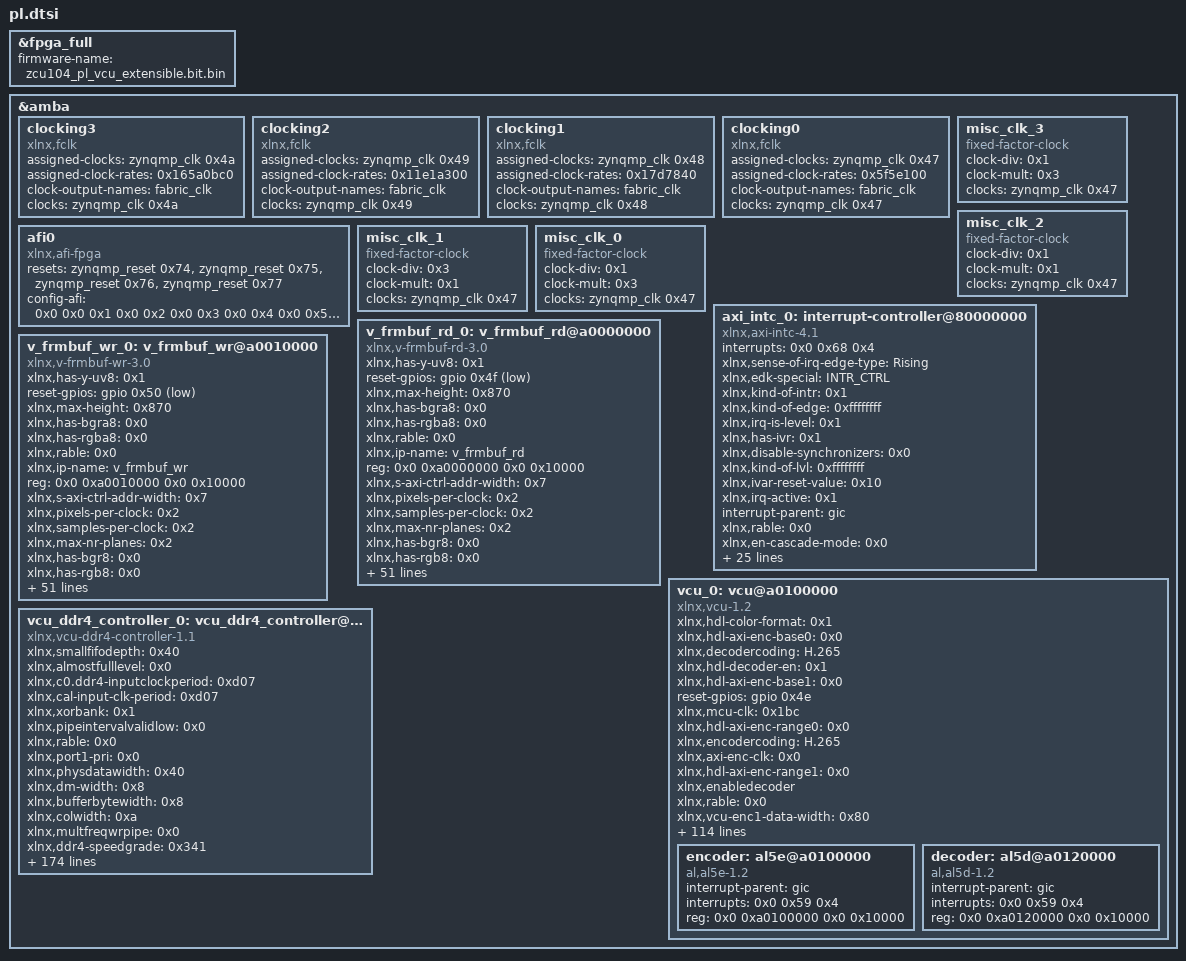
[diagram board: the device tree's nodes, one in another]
/dts-v1/;
/plugin/;
&fpga_full{
	firmware-name = "zcu104_pl_vcu_extensible.bit.bin";
};
&amba{
	clocking3: clocking3 {
		compatible = "xlnx,fclk";
		status = "okay";
		assigned-clocks = <&zynqmp_clk 0x4a>;
		assigned-clock-rates = <0x165a0bc0>;
		#clock-cells = <0x0>;
		clock-output-names = "fabric_clk";
		clocks = <&zynqmp_clk 0x4a>;
	};
	clocking2: clocking2 {
		compatible = "xlnx,fclk";
		status = "okay";
		assigned-clocks = <&zynqmp_clk 0x49>;
		assigned-clock-rates = <0x11e1a300>;
		#clock-cells = <0x0>;
		clock-output-names = "fabric_clk";
		clocks = <&zynqmp_clk 0x49>;
	};
	clocking1: clocking1 {
		compatible = "xlnx,fclk";
		status = "okay";
		assigned-clocks = <&zynqmp_clk 0x48>;
		assigned-clock-rates = <0x17d7840>;
		#clock-cells = <0x0>;
		clock-output-names = "fabric_clk";
		clocks = <&zynqmp_clk 0x48>;
	};
	clocking0: clocking0 {
		compatible = "xlnx,fclk";
		status = "okay";
		assigned-clocks = <&zynqmp_clk 0x47>;
		assigned-clock-rates = <0x5f5e100>;
		#clock-cells = <0x0>;
		clock-output-names = "fabric_clk";
		clocks = <&zynqmp_clk 0x47>;
	};
	afi0: afi0 {
		status = "okay";
		compatible = "xlnx,afi-fpga";
		resets = <&zynqmp_reset 0x74>,
<&zynqmp_reset 0x75>,
<&zynqmp_reset 0x76>,
<&zynqmp_reset 0x77>;
		config-afi = <0x0 0x0 0x1 0x0 0x2 0x0 0x3 0x0 0x4 0x0 0x5 0x0 0x6 0x0 0x7 0x0 0x8 0x0 0x9 0x0 0xa 0x0 0xb 0x0 0xc 0x0 0xd 0x0 0xe 0xa00 0xf 0x0>;
	};
};
&amba{
	misc_clk_3: misc_clk_3 {
		clock-div = <0x1>;
		compatible = "fixed-factor-clock";
		clock-mult = <0x3>;
		clocks = <&zynqmp_clk 0x47>;
		#clock-cells = <0x0>;
	};
	misc_clk_2: misc_clk_2 {
		clock-div = <0x1>;
		compatible = "fixed-factor-clock";
		clock-mult = <0x1>;
		clocks = <&zynqmp_clk 0x47>;
		#clock-cells = <0x0>;
	};
	misc_clk_1: misc_clk_1 {
		clock-div = <0x3>;
		compatible = "fixed-factor-clock";
		clock-mult = <0x1>;
		clocks = <&zynqmp_clk 0x47>;
		#clock-cells = <0x0>;
	};
	misc_clk_0: misc_clk_0 {
		clock-div = <0x1>;
		compatible = "fixed-factor-clock";
		clock-mult = <0x3>;
		clocks = <&zynqmp_clk 0x47>;
		#clock-cells = <0x0>;
	};
	axi_intc_0: interrupt-controller@80000000 {
		#interrupt-cells = <0x2>;
		interrupts = <0x0 0x68 0x4>;
		xlnx,sense-of-irq-edge-type = "Rising";
		xlnx,edk-special = "INTR_CTRL";
		xlnx,kind-of-intr = <0x1>;
		xlnx,kind-of-edge = <0xffffffff>;
		xlnx,irq-is-level = <0x1>;
		xlnx,has-ivr = <0x1>;
		compatible = "xlnx,axi-intc-4.1", "xlnx,xps-intc-1.00.a";
		xlnx,disable-synchronizers = <0x0>;
		xlnx,kind-of-lvl = <0xffffffff>;
		xlnx,ivar-reset-value = <0x10>;
		xlnx,irq-active = <0x1>;
		interrupt-parent = <&gic>;
		xlnx,rable = <0x0>;
		xlnx,en-cascade-mode = <0x0>;
		xlnx,ip-name = "axi_intc";
		xlnx,has-ilr = <0x0>;
		reg = <0x0 0x80000000 0x0 0x10000>;
		xlnx,addr-width = <0x20>;
		clocks = <&zynqmp_clk 0x47>;
		xlnx,s-axi-aclk-freq-mhz = <0x64>;
		xlnx,num-sw-intr = <0x0>;
		xlnx,irq-connection = <0x1>;
		xlnx,num-intr-inputs = <0x1>;
		xlnx,has-sie = <0x1>;
		xlnx,enable-async = <0x0>;
		xlnx,has-cie = <0x1>;
		xlnx,num-sync-ff = <0x2>;
		xlnx,edk-iptype = "PERIPHERAL";
		xlnx,mb-clk-not-connected = <0x1>;
		xlnx,has-ipr = <0x1>;
		xlnx,sense-of-irq-level-type = "Active_High";
		xlnx,cascade-master = <0x0>;
		xlnx,processor-clk-freq-mhz = <0x64>;
		status = "okay";
		xlnx,is-fast = <0x0>;
		clock-names = "s_axi_aclk";
		xlnx,has-fast = <0x0>;
		xlnx,ivar-rst-val = <0x10>;
		interrupt-controller;
		interrupt-names = "irq";
		xlnx,async-intr = <0xffffffff>;
		xlnx,name = "axi_intc_0";
	};
	v_frmbuf_rd_0: v_frmbuf_rd@a0000000 {
		xlnx,has-y-uv8 = <0x1>;
		reset-gpios = <&gpio 0x4f 0x1>;
		xlnx,max-height = <0x870>;
		xlnx,has-bgra8 = <0x0>;
		xlnx,has-rgba8 = <0x0>;
		xlnx,rable = <0x0>;
		xlnx,ip-name = "v_frmbuf_rd";
		reg = <0x0 0xa0000000 0x0 0x10000>;
		xlnx,s-axi-ctrl-addr-width = <0x7>;
		xlnx,pixels-per-clock = <0x2>;
		xlnx,samples-per-clock = <0x2>;
		xlnx,max-nr-planes = <0x2>;
		xlnx,has-bgr8 = <0x0>;
		xlnx,has-rgb8 = <0x0>;
		xlnx,has-y-uv8-420 = <0x1>;
		xlnx,has-yuyv8 = <0x0>;
		xlnx,has-y-u-v8 = <0x0>;
		interrupt-names = "interrupt";
		compatible = "xlnx,v-frmbuf-rd-3.0", "xlnx,axi-frmbuf-rd-v2.2";
		xlnx,max-width = <0xf00>;
		xlnx,has-rgb16 = <0x0>;
		xlnx,vid-formats = "y8", "y10", "nv12", "nv16", "xv20", "xv15";
		xlnx,has-bgrx8 = <0x0>;
		xlnx,has-rgbx8 = <0x0>;
		xlnx,has-rgbx10 = <0x0>;
		interrupt-parent = <&gic>;
		xlnx,aximm-num-outstanding = <0x4>;
		xlnx,has-uyvy8 = <0x0>;
		xlnx,has-rgbx12 = <0x0>;
		xlnx,aximm-burst-length = <0x10>;
		xlnx,aximm-addr-width = <0x40>;
		xlnx,video-width = <0xa>;
		xlnx,max-cols = <0xf00>;
		xlnx,has-yuv8 = <0x0>;
		status = "okay";
		xlnx,has-y-uv10-420 = <0x1>;
		xlnx,has-yuva8 = <0x0>;
		xlnx,has-y-uv12-420 = <0x0>;
		xlnx,name = "v_frmbuf_rd_0";
		interrupts = <0x0 0x5a 0x4>;
		xlnx,has-y10 = <0x1>;
		xlnx,has-y-uv16-420 = <0x0>;
		xlnx,has-y12 = <0x0>;
		xlnx,has-alpha = <0x0>;
		xlnx,has-y-u-v10 = <0x0>;
		clocks = <&misc_clk_0>;
		xlnx,has-y16 = <0x0>;
		xlnx,dma-align = <0x10>;
		xlnx,has-y-u-v12 = <0x0>;
		xlnx,edk-iptype = "PERIPHERAL";
		xlnx,has-interlaced = <0x0>;
		xlnx,has-yuv16 = <0x0>;
		xlnx,has-yuvx8 = <0x0>;
		xlnx,is-tile-format = <0x0>;
		xlnx,dma-addr-width = <0x40>;
		clock-names = "ap_clk";
		xlnx,s-axi-ctrl-data-width = <0x20>;
		xlnx,has-y8 = <0x1>;
		xlnx,has-y-uv10 = <0x1>;
		xlnx,has-y-uv12 = <0x0>;
		xlnx,max-rows = <0x870>;
		xlnx,has-yuvx10 = <0x0>;
		#dma-cells = <0x1>;
		xlnx,has-yuvx12 = <0x0>;
		xlnx,has-y-uv16 = <0x0>;
		xlnx,max-data-width = <0xa>;
		xlnx,has-y-u-v8-420 = <0x0>;
		xlnx,num-video-components = <0x3>;
		xlnx,aximm-data-width = <0x80>;
	};
	v_frmbuf_wr_0: v_frmbuf_wr@a0010000 {
		xlnx,has-y-uv8 = <0x1>;
		reset-gpios = <&gpio 0x50 0x1>;
		xlnx,max-height = <0x870>;
		xlnx,has-bgra8 = <0x0>;
		xlnx,has-rgba8 = <0x0>;
		xlnx,rable = <0x0>;
		xlnx,ip-name = "v_frmbuf_wr";
		reg = <0x0 0xa0010000 0x0 0x10000>;
		xlnx,s-axi-ctrl-addr-width = <0x7>;
		xlnx,pixels-per-clock = <0x2>;
		xlnx,samples-per-clock = <0x2>;
		xlnx,max-nr-planes = <0x2>;
		xlnx,has-bgr8 = <0x0>;
		xlnx,has-rgb8 = <0x0>;
		xlnx,has-y-uv8-420 = <0x1>;
		xlnx,has-yuyv8 = <0x0>;
		xlnx,has-y-u-v8 = <0x0>;
		interrupt-names = "interrupt";
		compatible = "xlnx,v-frmbuf-wr-3.0", "xlnx,axi-frmbuf-wr-v2.2";
		xlnx,max-width = <0xf00>;
		xlnx,has-rgb16 = <0x0>;
		xlnx,vid-formats = "y8", "y10", "nv12", "nv16", "xv20", "xv15";
		xlnx,has-bgrx8 = <0x0>;
		xlnx,has-rgbx8 = <0x0>;
		xlnx,has-rgbx10 = <0x0>;
		interrupt-parent = <&gic>;
		xlnx,aximm-num-outstanding = <0x4>;
		xlnx,has-uyvy8 = <0x0>;
		xlnx,has-rgbx12 = <0x0>;
		xlnx,aximm-burst-length = <0x10>;
		xlnx,aximm-addr-width = <0x20>;
		xlnx,video-width = <0xa>;
		xlnx,max-cols = <0xf00>;
		xlnx,has-yuv8 = <0x0>;
		status = "okay";
		xlnx,has-y-uv10-420 = <0x1>;
		xlnx,has-yuva8 = <0x0>;
		xlnx,has-y-uv12-420 = <0x0>;
		xlnx,name = "v_frmbuf_wr_0";
		interrupts = <0x0 0x5b 0x4>;
		xlnx,has-y10 = <0x1>;
		xlnx,has-y-uv16-420 = <0x0>;
		xlnx,has-y12 = <0x0>;
		xlnx,has-alpha = <0x0>;
		xlnx,has-y-u-v10 = <0x0>;
		clocks = <&misc_clk_0>;
		xlnx,has-y16 = <0x0>;
		xlnx,dma-align = <0x10>;
		xlnx,has-y-u-v12 = <0x0>;
		xlnx,edk-iptype = "PERIPHERAL";
		xlnx,has-interlaced = <0x0>;
		xlnx,has-yuv16 = <0x0>;
		xlnx,has-yuvx8 = <0x0>;
		xlnx,is-tile-format = <0x0>;
		xlnx,dma-addr-width = <0x20>;
		clock-names = "ap_clk";
		xlnx,s-axi-ctrl-data-width = <0x20>;
		xlnx,has-y8 = <0x1>;
		xlnx,has-y-uv10 = <0x1>;
		xlnx,has-y-uv12 = <0x0>;
		xlnx,max-rows = <0x870>;
		xlnx,has-yuvx10 = <0x0>;
		#dma-cells = <0x1>;
		xlnx,has-yuvx12 = <0x0>;
		xlnx,has-y-uv16 = <0x0>;
		xlnx,max-data-width = <0xa>;
		xlnx,has-y-u-v8-420 = <0x0>;
		xlnx,num-video-components = <0x3>;
		xlnx,aximm-data-width = <0x80>;
	};
	vcu_0: vcu@a0100000 {
		xlnx,hdl-color-format = <0x1>;
		xlnx,hdl-axi-enc-base0 = <0x0>;
		xlnx,decodercoding = "H.265";
		xlnx,hdl-decoder-en = <0x1>;
		xlnx,hdl-axi-enc-base1 = <0x0>;
		reset-gpios = <&gpio 0x4e 0x0>;
		xlnx,mcu-clk = <0x1bc>;
		xlnx,hdl-axi-enc-range0 = <0x0>;
		xlnx,encodercoding = "H.265";
		xlnx,axi-enc-clk = <0x0>;
		xlnx,hdl-axi-enc-range1 = <0x0>;
		xlnx,enabledecoder;
		xlnx,rable = <0x0>;
		xlnx,vcu-enc1-data-width = <0x80>;
		xlnx,dec-video-standard = <0x0>;
		xlnx,pll-bypass = <0x0>;
		xlnx,hdl-dec-fps = <0x3c>;
		xlnx,encverresolution = <0x870>;
		xlnx,enc-mem-bram-used = <0x0>;
		xlnx,ip-name = "vcu";
		#size-cells = <0x2>;
		reg = <0x0 0xa0140000 0x0 0x1000 0x0 0xa0141000 0x0 0x1000>;
		xlnx,hdl-enc-clk = <0x0>;
		xlnx,hdl-enc-buffer-en = <0x1>;
		#address-cells = <0x2>;
		xlnx,hdl-axi-mcu-range = <0x0>;
		xlnx,vcu-dec0-data-width = <0x80>;
		xlnx,enc-fps = <0x1>;
		xlnx,dec-coding-type = <0x1>;
		xlnx,axi-enc-range0 = <0x0>;
		interrupt-names = "vcu_host_interrupt";
		xlnx,hdl-vcu-test-en = <0x0>;
		xlnx,hdl-coding-type = <0x1>;
		xlnx,enc-color-format = <0x1>;
		xlnx,axi-enc-range1 = <0x0>;
		xlnx,decoderchromaformat = "4_2_2";
		compatible = "xlnx,vcu-1.2", "xlnx,vcu";
		xlnx,vcu-axiliteapb-data-width = <0x20>;
		xlnx,dec-color-depth = <0x1>;
		xlnx,enable-encoder;
		xlnx,hdl-encoder-en = <0x1>;
		xlnx,decverresolution = <0x870>;
		interrupt-parent = <&gic>;
		xlnx,hdl-dec-frame-size-x = <0xf00>;
		xlnx,hdl-color-depth = <0x1>;
		xlnx,hdl-dec-frame-size-y = <0x870>;
		xlnx,hdl-axi-mcu-clk = <0x40533333>;
		xlnx,enc-video-standard = <0x0>;
		ranges;
		xlnx,enc-mem-uram-used = <0x6ae>;
		xlnx,decodernumcores = <0x2>;
		xlnx,no-of-streams = <0x8>;
		xlnx,hdl-dec-video-standard = <0x0>;
		xlnx,axi-mcu-clk = <0x14a>;
		xlnx,hdl-pll-bypass = <0x0>;
		xlnx,enc-buffer-manual-override = <0x0>;
		status = "okay";
		xlnx,dec-color-format = <0x1>;
		xlnx,pll-clk = <0x1fca055>;
		xlnx,hdl-test-port-en = <0x0>;
		xlnx,hdl-axi-dec-clk = <0x0>;
		xlnx,hdl-mcu-clk = <0x1bc>;
		xlnx,hdl-axi-mcu-base = <0x0>;
		xlnx,name = "vcu_0";
		interrupts = <0x0 0x59 0x4>;
		xlnx,table-no = <0x1>;
		xlnx,axi-dec-clk = <0x0>;
		xlnx,hdl-dec-color-format = <0x1>;
		xlnx,hdl-ram-type = <0x0>;
		xlnx,hdl-pll-clk-lo = <0x20>;
		xlnx,enc-buffer-size-actual = <0x6ae>;
		xlnx,vcu-dec1-data-width = <0x80>;
		xlnx,vcu-mcu-data-width = <0x20>;
		xlnx,dec-frame-size = <0x4>;
		xlnx,enc-buffer-size = <0x5f0>;
		xlnx,hdl-table-no = <0x1>;
		xlnx,enableencoder;
		clocks = <&misc_clk_1>,
<&misc_clk_2>,
<&vcu_0 0x0>,
<&vcu_0 0x1>,
<&vcu_0 0x2>,
<&vcu_0 0x3>;
		xlnx,hdl-dec-coding-type = <0x1>;
		xlnx,hdl-video-standard = <0x0>;
		xlnx,dec-fps = <0x3>;
		xlnx,edk-iptype = "PERIPHERAL";
		xlnx,enc-buffer-b-frame = <0x1>;
		xlnx,enc-clk = <0x0>;
		xlnx,vcu-enc0-data-width = <0x80>;
		xlnx,hdl-fps = <0x1e>;
		xlnx,enc-coding-type = <0x1>;
		clock-names = "pll_ref", "aclk", "vcu_core_enc", "vcu_mcu_enc", "vcu_core_dec", "vcu_mcu_dec";
		xlnx,hdl-dec-color-depth = <0x1>;
		xlnx,hdl-enc-buffer-motion-vec-range = <0x0>;
		xlnx,hdl-enc-buffer-manual-override = <0x0>;
		xlnx,hdl-axi-dec-range0 = <0x0>;
		xlnx,enable-decoder;
		xlnx,hdl-axi-dec-range1 = <0x0>;
		xlnx,encoderchromaformat = "4_2_2";
		xlnx,enchorresolution = <0xf00>;
		xlnx,axi-dec-base0 = <0x0>;
		xlnx,no-of-dec-streams = <0x1>;
		xlnx,hdl-wpp-en = <0x0>;
		xlnx,enc-color-depth = <0x1>;
		xlnx,enc-buffer-type = <0x0>;
		xlnx,axi-dec-base1 = <0x0>;
		xlnx,decodercodingtype = "INTRA_ONLY";
		xlnx,hdl-frame-size-x = <0x780>;
		xlnx,axi-enc-base0 = <0x0>;
		xlnx,enc-buffer-motion-vec-range = <0x0>;
		xlnx,hdl-frame-size-y = <0x438>;
		xlnx,encodercodingtype = "INTRA_ONLY";
		xlnx,enc-frame-size = <0x3>;
		xlnx,axi-enc-base1 = <0x0>;
		xlnx,core-clk = <0x29b>;
		xlnx,hdl-num-concurrent-streams = <0x4>;
		xlnx,hdl-pll-clk-hi = <0x21>;
		xlnx,decodercolordepth = <0xa>;
		xlnx,encodernumcores = <0x4>;
		xlnx,encodercolordepth = <0xa>;
		xlnx,axi-mcu-base = <0x0>;
		xlnx,hdl-core-clk = <0x29b>;
		xlnx,axi-dec-range0 = <0x0>;
		xlnx,enc-buffer-en;
		xlnx,hdl-mem-depth = <0x9800>;
		xlnx,axi-dec-range1 = <0x0>;
		xlnx,axi-mcu-range = <0x0>;
		xlnx,wpp-en = <0x0>;
		xlnx,hdl-axi-dec-base0 = <0x0>;
		reg-names = "vcu_slcr", "logicore";
		#clock-cells = <0x1>;
		xlnx,mcu-debug = <0x0>;
		xlnx,hdl-num-streams = <0x8>;
		xlnx,hdl-max-num-cores = <0x4>;
		xlnx,hdl-enc-buffer-b-frame = <0x1>;
		xlnx,hdl-axi-enc-clk = <0x0>;
		xlnx,hdl-axi-dec-base1 = <0x0>;
		xlnx,coreclkfreq = <0x29b>;
		xlnx,dechorresolution = <0xf00>;
	
		encoder: al5e@a0100000 {
			interrupt-parent = <&gic>;
			interrupts = <0x0 0x59 0x4>;
			compatible = "al,al5e-1.2", "al,al5e";
			reg = <0x0 0xa0100000 0x0 0x10000>;
		};
		decoder: al5d@a0120000 {
			interrupt-parent = <&gic>;
			interrupts = <0x0 0x59 0x4>;
			compatible = "al,al5d-1.2", "al,al5d";
			reg = <0x0 0xa0120000 0x0 0x10000>;
		};
		};
	vcu_ddr4_controller_0: vcu_ddr4_controller@4800000000 {
		xlnx,smallfifodepth = <0x40>;
		xlnx,almostfulllevel = <0x0>;
		xlnx,c0.ddr4-inputclockperiod = <0xd07>;
		xlnx,cal-input-clk-period = <0xd07>;
		xlnx,xorbank = <0x1>;
		xlnx,pipeintervalvalidlow = <0x0>;
		xlnx,rable = <0x0>;
		xlnx,port1-pri = <0x0>;
		xlnx,physdatawidth = <0x40>;
		xlnx,dm-width = <0x8>;
		xlnx,bufferbytewidth = <0x8>;
		xlnx,colwidth = <0xa>;
		xlnx,multfreqwrpipe = <0x0>;
		xlnx,ddr4-speedgrade = <0x341>;
		xlnx,ip-name = "vcu_ddr4_controller";
		xlnx,port3-pri = <0x1>;
		xlnx,pipeintervalwaithigh = <0x3>;
		xlnx,ddr4-custompartsfile = "no_file_loaded";
		reg = <0x48 0x0 0x0 0x80000000>;
		xlnx,usrwrpipe = <0x1>;
		xlnx,nbseq = <0x1>;
		xlnx,logenable = <0x0>;
		xlnx,data-buf-addr-width = <0x5>;
		xlnx,cust-ddr4-timeperiod = <0x341>;
		xlnx,hdl-port0-en = <0x1>;
		xlnx,dualclock = <0x0>;
		xlnx,ddr4-cmdgetaddr = <0x16>;
		xlnx,writedelay = <0x7>;
		xlnx,burstlength = <0x8>;
		xlnx,nbchipselect = <0x1>;
		xlnx,iaddrwidth = <0x16>;
		xlnx,bankwidth = <0x4>;
		xlnx,bufferdatawidth = <0x80>;
		xlnx,clkout1-divide-mmcm = <0x6>;
		xlnx,nbfifo = <0x10>;
		xlnx,odtend = <0x6>;
		xlnx,nrtr = <0xd>;
		xlnx,dram-width-hdl = <0x0>;
		xlnx,divclk-divide-mmcm = <0x3>;
		xlnx,cust-csv-memtype = "Components";
		xlnx,ddr4-cust-file-en = <0x0>;
		xlnx,data-width = <0x0>;
		xlnx,cwlatency = <0xe>;
		compatible = "xlnx,vcu-ddr4-controller-1.1";
		xlnx,c0-ddr4-divclk-divide = <0x3>;
		xlnx,nrtw = <0x3>;
		xlnx,cmdrep = <0x0>;
		xlnx,speed-bin-hdl = <0x1>;
		xlnx,areset = <0x0>;
		xlnx,c0-ddr4-clkfbout-mult = <0x10>;
		xlnx,nodatacmdslot = <0x3>;
		xlnx,hdl-port3-en = <0x1>;
		xlnx,dimm-value-hdl = <0x0>;
		xlnx,ddr4-sdrambank = <0x10>;
		xlnx,trfc = <0x104>;
		xlnx,physaddrwidth = <0x11>;
		xlnx,wrpipe = <0x1>;
		xlnx,caslatency = <0xf>;
		xlnx,c0.ddr4-clkout0-divide = <0x6>;
		xlnx,drivestrength = <0x0>;
		xlnx,ddr4-cmdflag = <0x10>;
		xlnx,rddatafifopipe = <0x1>;
		xlnx,resetlevel = <0x1>;
		xlnx,ref-clk = <0x12c>;
		xlnx,nfaw = <0x6>;
		xlnx,maxpostedrefresh = <0x1>;
		xlnx,ddr4-cmdwait = <0x10>;
		xlnx,cust-csv-clkout2-freq = <0x12c>;
		xlnx,twr = <0xf>;
		xlnx,coldelay = <0x4>;
		xlnx,writegrouping = <0x20>;
		status = "okay";
		xlnx,c0.ddr4-timeperiod = <0x3aa>;
		xlnx,port0-pri-idx = <0x1>;
		xlnx,dbgmoncntsize = <0x10>;
		xlnx,c0.controllertype = "ddr4_sdram";
		xlnx,combineaxiburst = <0x1>;
		xlnx,rowwidth = <0xf>;
		xlnx,port1-pri-idx = <0x2>;
		xlnx,port2-pri-idx = <0x4>;
		xlnx,enable-port0;
		xlnx,name = "vcu_ddr4_controller_0";
		xlnx,usrburstwidth = <0x8>;
		xlnx,tck = <0x3aa>;
		xlnx,port3-pri-idx = <0x5>;
		xlnx,enable-port1;
		xlnx,ddr = <0x4>;
		xlnx,port4-pri-idx = <0x3>;
		xlnx,nwtr = <0x7>;
		xlnx,no-of-axi-ports = <0x5>;
		xlnx,nbcke = <0x1>;
		xlnx,hdl-port1-en = <0x1>;
		xlnx,enable-port2;
		xlnx,cust-enable = <0x0>;
		xlnx,c0.ddr4-divclk-divide = <0x3>;
		xlnx,incrburst = <0x0>;
		xlnx,fastfaw = <0x0>;
		xlnx,enable-port3;
		xlnx,nbbank = <0x10>;
		xlnx,port0-pri = <0x0>;
		xlnx,enable-port4;
		xlnx,dqs-width = <0x8>;
		xlnx,c0.ddr4-clkfbout-mult = <0x10>;
		xlnx,trace-length = <0x3>;
		xlnx,clkinperiodmmcm = <0xd07>;
		xlnx,readgrouping = <0x60>;
		xlnx,port2-pri = <0x1>;
		xlnx,ping-pong = <0x1>;
		xlnx,cust-csv-datawidth = <0x40>;
		xlnx,nwtw = <0x10>;
		xlnx,multfreq = <0x1>;
		xlnx,memory-timeperiod = <0x64>;
		xlnx,dram-speed-bin = <0x2>;
		xlnx,ddr4-customparts = "no_file_loaded";
		clocks = <&misc_clk_3>;
		xlnx,regcmdaddrincr = <0x0>;
		xlnx,port4-pri = <0x0>;
		xlnx,addrpipe = <0x0>;
		xlnx,nbhiprior-ports = <0x3>;
		xlnx,pipeintervalvalidhigh = <0x3>;
		xlnx,addrwidth = <0x1a>;
		xlnx,ck-width = <0x1>;
		xlnx,clkout0-divide-mmcm = <0x6>;
		xlnx,edk-iptype = "PERIPHERAL";
		xlnx,perrd = <0x1>;
		xlnx,addn-ui-clkout2-freq-hz = <0x10b>;
		xlnx,clkout2-divide-mmcm = <0x6>;
		xlnx,hdl-port4-en = <0x1>;
		xlnx,fifo-depth = <0x100>;
		xlnx,ddr4-cmdstrobe = <0x10>;
		xlnx,bg-width = <0x1>;
		xlnx,c0-controllertype = <0x0>;
		xlnx,choose-ram = <0x0>;
		xlnx,clkfboutmultmmcm = <0x10>;
		xlnx,nrrd = <0x1>;
		clock-names = "S_Axi_Clk";
		xlnx,trpa = <0x3a96>;
		xlnx,nzqcs = <0x40>;
		xlnx,maddrwidth = <0x1a>;
		xlnx,ddr4-cmdtoken = <0x10>;
		xlnx,wrpipebram = <0x1>;
		xlnx,replicatefract = <0x1>;
		xlnx,dram-width = <0x0>;
		xlnx,ddr4-tck-op = <0x2ee>;
		xlnx,trefi = <0x1e78>;
		xlnx,ref-clk-var = <0xd07>;
		xlnx,enable-decoder;
		xlnx,axi-addrwidth = <0x20>;
		xlnx,waitfast = <0x0>;
		xlnx,maxdatasize = <0x800>;
		xlnx,ddraxiburstratio = <0x2>;
		xlnx,wr-port0-pri-idx = <0x1>;
		xlnx,odtstart = <0x4>;
		xlnx,wr-port1-pri-idx = <0x2>;
		xlnx,tzqcsi = <0x100>;
		xlnx,rdpipebram = <0x0>;
		xlnx,part-sg = <0x2>;
		xlnx,mc-bg = <0xf>;
		xlnx,nrrd-s = <0x0>;
		xlnx,clkout2-divide = <0x6>;
		xlnx,wr-port2-pri-idx = <0x3>;
		xlnx,chipgrouping = <0x4>;
		xlnx,wrack = <0x1>;
		xlnx,wr-port3-pri-idx = <0x4>;
		xlnx,is-cke-shared = <0x0>;
		xlnx,active-axi-ports = <0x5>;
		xlnx,wr-port4-pri-idx = <0x5>;
		xlnx,ddr4-op-clk = <0x12c>;
		xlnx,csv-file-en = <0x0>;
		xlnx,bankgroupwidth = <0x2>;
		xlnx,compbits = <0x2710>;
		xlnx,pipeintervalwaitlow = <0x0>;
		xlnx,gui-csv-ddr4-custompartsfile = "no_file_loaded";
		xlnx,gui-csv-ddr4-customparts = "no_file_loaded";
		xlnx,ddr4-inputclk-period-ip = <0x9c4>;
		xlnx,usrflag = <0x10>;
		xlnx,rdpipe = <0x0>;
		xlnx,odt-width = <0x1>;
		xlnx,norefresh = <0x0>;
		xlnx,hdl-port2-en = <0x1>;
		xlnx,hdl-nobuffer = <0x0>;
		xlnx,dqwidth = <0x40>;
		xlnx,cust-csv-partname = "MT40A1G8SA-075:E";
		xlnx,op-clk = <0x12c>;
		xlnx,dimm-type = <0x0>;
		xlnx,nck-per-clk = <0x4>;
		xlnx,m-addn-ui-clkout2-freq-hz = <0x0>;
		xlnx,ddr4-cmdindex = <0x80>;
		xlnx,c0-ddr4-clkout0-divide = <0x6>;
		xlnx,initbyphy = <0x1>;
	};
};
